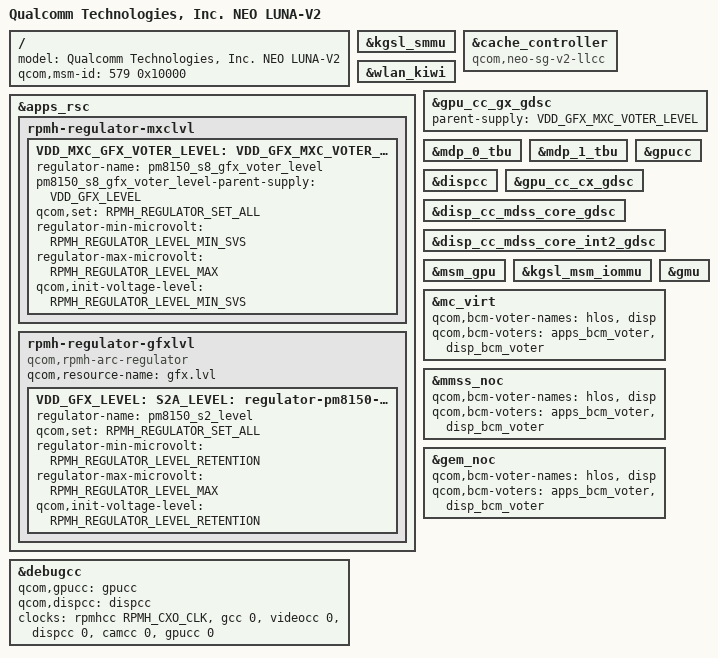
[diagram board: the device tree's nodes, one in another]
#include "neo_la.dtsi"
#include "neo-pm8008.dtsi"

/ {
	model = "Qualcomm Technologies, Inc. NEO LUNA-V2";
	qcom,msm-id = <579 0x10000>;
};

&kgsl_smmu {
	status = "ok";
};

&cache_controller {
	compatible = "qcom,neo-sg-v2-llcc", "qcom,llcc-v31";
};

&wlan_kiwi {
	/delete-property/ vdd-wlan-supply;
	/delete-property/ qcom,pdc_init_table;
	/delete-property/ qcom,vreg_pdc_map;
	/delete-property/ qcom,pmu_vreg_map;
};

&apps_rsc {
	/* Delete S2A VRM for WLAN on neo_luna-v2*/
	/delete-node/ rpmh-regulator-smpa2;

	rpmh-regulator-mxclvl {
		VDD_MXC_GFX_VOTER_LEVEL: VDD_GFX_MXC_VOTER_LEVEL:
		regulator-pm8150-s8-gfx-voter-level {
			regulator-name = "pm8150_s8_gfx_voter_level";
			pm8150_s8_gfx_voter_level-parent-supply =
				<&VDD_GFX_LEVEL>;
			qcom,set = <RPMH_REGULATOR_SET_ALL>;
			regulator-min-microvolt =
				<RPMH_REGULATOR_LEVEL_MIN_SVS>;
			regulator-max-microvolt =
				<RPMH_REGULATOR_LEVEL_MAX>;
			qcom,init-voltage-level =
				<RPMH_REGULATOR_LEVEL_MIN_SVS>;
		};
	};

	rpmh-regulator-gfxlvl {
		compatible = "qcom,rpmh-arc-regulator";
		qcom,resource-name = "gfx.lvl";
		VDD_GFX_LEVEL: S2A_LEVEL:
		pm8150_s2_level: regulator-pm8150-s2-level {
			regulator-name = "pm8150_s2_level";
			qcom,set = <RPMH_REGULATOR_SET_ALL>;
			regulator-min-microvolt =
				<RPMH_REGULATOR_LEVEL_RETENTION>;
			regulator-max-microvolt =
				<RPMH_REGULATOR_LEVEL_MAX>;
			qcom,init-voltage-level =
				<RPMH_REGULATOR_LEVEL_RETENTION>;
		};
	};
};

&gpu_cc_gx_gdsc {
	parent-supply = <&VDD_GFX_MXC_VOTER_LEVEL>;
};

&mdp_0_tbu {
	status = "ok";
};

&mdp_1_tbu {
	status = "ok";
};

&gpucc {
	status = "ok";
};

&dispcc {
	status = "ok";
};

&debugcc {
	qcom,gpucc = <&gpucc>;
	qcom,dispcc = <&dispcc>;
	clock-names = "xo_clk_src",
			"gcc",
			"videocc",
			"dispcc",
			"camcc",
			"gpucc";
	clocks = <&rpmhcc RPMH_CXO_CLK>,
		<&gcc 0>,
		<&videocc 0>,
		<&dispcc 0>,
		<&camcc 0>,
		<&gpucc 0>;
};

&gpu_cc_cx_gdsc {
	status = "ok";
};

&gpu_cc_gx_gdsc {
	status = "ok";
};

&disp_cc_mdss_core_gdsc {
	status = "ok";
};

&disp_cc_mdss_core_int2_gdsc {
	status = "ok";
};

&msm_gpu {
	status = "ok";
};

&kgsl_msm_iommu {
	status = "ok";
};

&gmu {
	status = "ok";
};

&mc_virt {
	qcom,bcm-voter-names = "hlos", "disp";
	qcom,bcm-voters = <&apps_bcm_voter>, <&disp_bcm_voter>;
};

&mmss_noc {
	qcom,bcm-voter-names = "hlos", "disp";
	qcom,bcm-voters = <&apps_bcm_voter>, <&disp_bcm_voter>;
};

&gem_noc {
	qcom,bcm-voter-names = "hlos", "disp";
	qcom,bcm-voters = <&apps_bcm_voter>, <&disp_bcm_voter>;
};
